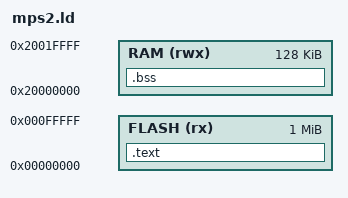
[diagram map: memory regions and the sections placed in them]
OUTPUT_FORMAT("elf32-littlearm")
ENTRY(Reset_Handler)

MEMORY {
    FLASH (rx) : ORIGIN = 0x00000000, LENGTH = 1024K
    RAM (rwx) : ORIGIN = 0x20000000, LENGTH = 128K
}

_stack_top = ORIGIN(RAM) + LENGTH(RAM);

SECTIONS {
    .text : {
        KEEP(*(.isr_vector))
        *(.text*)
        *(.rodata*)
        . = ALIGN(4);
    } > FLASH

    .bss : {
        . = ALIGN(4);
        _sbss = .;
        *(.bss*)
        *(COMMON)
        . = ALIGN(4);
        _ebss = .;
    } > RAM
}
